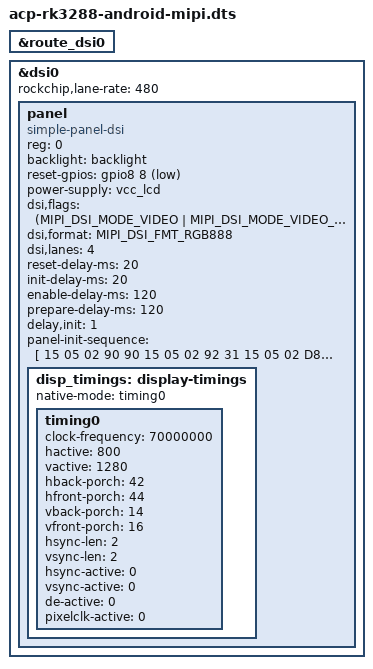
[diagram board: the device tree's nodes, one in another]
/*
 * This file is dual-licensed: you can use it either under the terms
 * of the GPL or the X11 license, at your option. Note that this dual
 * licensing only applies to this file, and not this project as a
 * whole.
 *
 *  a) This file is free software; you can redistribute it and/or
 *     modify it under the terms of the GNU General Public License as
 *     published by the Free Software Foundation; either version 2 of the
 *     License, or (at your option) any later version.
 *
 *     This file is distributed in the hope that it will be useful,
 *     but WITHOUT ANY WARRANTY; without even the implied warranty of
 *     MERCHANTABILITY or FITNESS FOR A PARTICULAR PURPOSE.  See the
 *     GNU General Public License for more details.
 *
 * Or, alternatively,
 *
 *  b) Permission is hereby granted, free of charge, to any person
 *     obtaining a copy of this software and associated documentation
 *     files (the "Software"), to deal in the Software without
 *     restriction, including without limitation the rights to use,
 *     copy, modify, merge, publish, distribute, sublicense, and/or
 *     sell copies of the Software, and to permit persons to whom the
 *     Software is furnished to do so, subject to the following
 *     conditions:
 *
 *     The above copyright notice and this permission notice shall be
 *     included in all copies or substantial portions of the Software.
 *
 *     THE SOFTWARE IS PROVIDED "AS IS", WITHOUT WARRANTY OF ANY KIND,
 *     EXPRESS OR IMPLIED, INCLUDING BUT NOT LIMITED TO THE WARRANTIES
 *     OF MERCHANTABILITY, FITNESS FOR A PARTICULAR PURPOSE AND
 *     NONINFRINGEMENT. IN NO EVENT SHALL THE AUTHORS OR COPYRIGHT
 *     HOLDERS BE LIABLE FOR ANY CLAIM, DAMAGES OR OTHER LIABILITY,
 *     WHETHER IN AN ACTION OF CONTRACT, TORT OR OTHERWISE, ARISING
 *     FROM, OUT OF OR IN CONNECTION WITH THE SOFTWARE OR THE USE OR
 *     OTHER DEALINGS IN THE SOFTWARE.
 */

/dts-v1/;
#include "acp-rk3288-android.dtsi"

&route_dsi0 {
	status = "okay";
};

&dsi0 {
	status = "okay";
	rockchip,lane-rate = <480>;

	panel: panel {
		compatible = "simple-panel-dsi";
		reg = <0>;
		backlight = <&backlight>;
		reset-gpios = <&gpio8 8 GPIO_ACTIVE_LOW>;
		power-supply = <&vcc_lcd>;
		dsi,flags = <(MIPI_DSI_MODE_VIDEO | MIPI_DSI_MODE_VIDEO_BURST | MIPI_DSI_MODE_LPM | MIPI_DSI_MODE_EOT_PACKET)>;
		dsi,format = <MIPI_DSI_FMT_RGB888>;
		dsi,lanes = <4>;
		reset-delay-ms = <20>;
		init-delay-ms = <20>;
		enable-delay-ms = <120>;
		prepare-delay-ms = <120>;
		delay,init = <1>;
		status = "okay";

		panel-init-sequence = [
			15 05 02 90 90
			15 05 02 92 31
			15 05 02 D8 66
			39 05 13 19 00 00 FC B5 F2 BF FF FB BF 91 00 00 00 1C F8 1F 01 FB
			39 05 13 19 10 00 92 5E 90 00 A0 2C 55 02 69 CE 64 59 20 0A DF 37
			39 05 13 19 20 00 E9 9D A7 87 C2 F7 4D 7E 17 A4 39 93 95 54 A1 50
			39 05 13 19 30 00 20 40 48 11 BA 54 E0 48 06 00 00 00 00 0E 7F 3F
			39 05 13 19 40 00 84 18 40 30 14 C2 FF 37 AC 04 00 00 78 89 03 C0
			39 05 13 19 50 00 00 62 80 00 E2 29 C2 86 14 21 FB 01 3C 00 14 64
			39 05 13 19 60 00 64 A0 10 0A 1E 1C 36 9C 08 01 3A 1E 80 91 02 3C
			39 05 13 19 70 00 86 3F 63 20 40 BA 86 8C 43 18 FE FE FE FE FE FE
			39 05 13 19 80 00 FE FE FE FE 00 01 01 01 01 01 01 01 01 01 01 E8
			39 05 13 19 90 00 0F 09 01 00 3C 20 85 24 0D 00 00 00 80 E6 66 00
			39 05 13 19 A0 00 00 00 00 00 00 2D 5A 00 00 00 00 00 00 88 60 20
			39 05 13 19 B0 00 28 50 A0 40 81 82 82 82 02 00 00 00 00 00 00 00
			39 05 13 19 C0 00 00 94 28 51 A2 44 49 49 49 09 00 00 00 00 00 00
			39 05 13 19 D0 00 00 00 00 03 3C 64 6E 00 00 00 00 00 82 82 14 14
			39 05 13 19 E0 00 82 82 14 14 A5 5A 96 96 A5 5A 96 96 EB EB 7D 7D
			39 05 13 19 F0 00 EB EB 7D 7D 00 00 12 84 00 00 48 21 12 84 48 21
			39 05 07 19 DC 01 21 48 84 12
			39 05 13 19 E0 01 12 84 69 69 48 21 A5 5A 69 69 A5 5A 96 96 5A A5
			39 05 13 19 F0 01 69 69 DE B7 A5 5A 7B ED DE B7 7B ED ED 7B B7 DE
			05 78 01 11
			05 32 01 29
		];

		disp_timings: display-timings {
			native-mode = <&timing0>;

			timing0: timing0 {
				clock-frequency = <70000000>;
				hactive = <800>;
				vactive = <1280>;
				hback-porch = <42>;
				hfront-porch = <44>;
				vback-porch = <14>;
				vfront-porch = <16>;
				hsync-len = <2>;
				vsync-len = <2>;
				hsync-active = <0>;
				vsync-active = <0>;
				de-active = <0>;
				pixelclk-active = <0>;
			};
		};
	};
};

